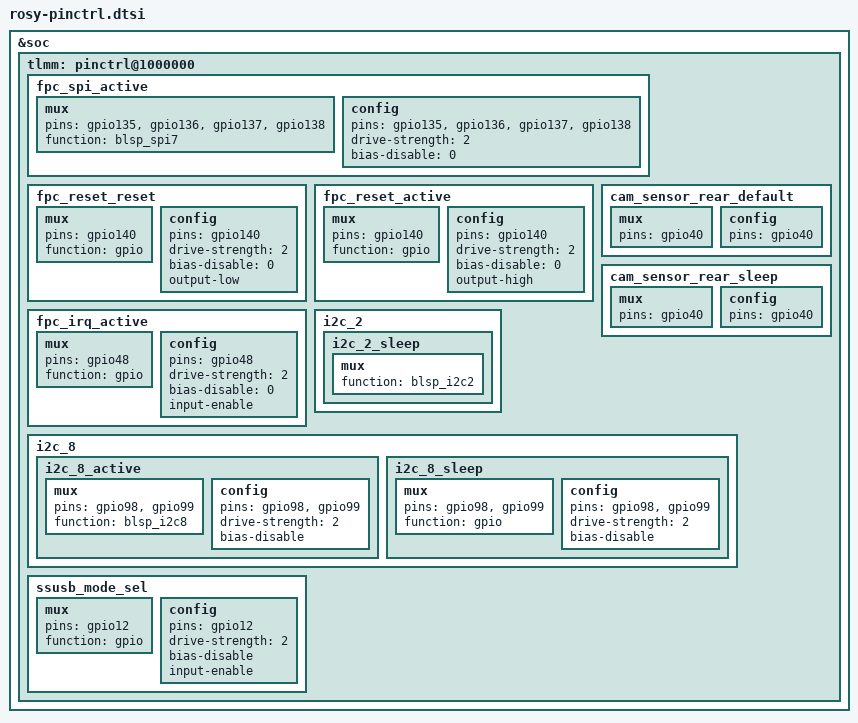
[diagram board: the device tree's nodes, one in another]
/*
 * Copyright (c) 2015-2018, The Linux Foundation. All rights reserved.
 * Copyright (C) 2019 XiaoMi, Inc.
 *
 * This program is free software; you can redistribute it and/or modify
 * it under the terms of the GNU General Public License version 2 and
 * only version 2 as published by the Free Software Foundation.
 *
 * This program is distributed in the hope that it will be useful,
 * but WITHOUT ANY WARRANTY; without even the implied warranty of
 * MERCHANTABILITY or FITNESS FOR A PARTICULAR PURPOSE.  See the
 * GNU General Public License for more details.
 */

&soc {
	tlmm: pinctrl@1000000 {
		fpc_spi_active: fpc_spi_active {
			mux {
				pins = "gpio135", "gpio136", "gpio137", "gpio138";
				function = "blsp_spi7";
			};

			config {
				pins = "gpio135", "gpio136", "gpio137", "gpio138";
				drive-strength = <2>;
				bias-disable = <0>;
			};
		};

		fpc_reset_reset: fpc_reset_reset{
			mux {
				pins = "gpio140";
				function = "gpio";
			};

			config {
				pins = "gpio140";
				drive-strength = <2>;
				bias-disable = <0>;
				output-low;
			};
		};

		fpc_reset_active: fpc_reset_active{
			mux {
				pins = "gpio140";
				function = "gpio";
			};

			config {
				pins = "gpio140";
				drive-strength = <2>;
				bias-disable = <0>;
				output-high;
			};
		};

		fpc_irq_active: fpc_irq_active {
			mux {
				pins = "gpio48";
				function = "gpio";
			};

			config {
				pins = "gpio48";
				drive-strength = <2>;
				bias-disable = <0>;
				input-enable;
			};
		};

		cam_sensor_rear_default: cam_sensor_rear_default {
			mux {
				pins = "gpio40";
			};

			config {
				pins = "gpio40";
			};
		};

		cam_sensor_rear_sleep: cam_sensor_rear_sleep {
			mux {
				pins = "gpio40";
			};

			config {
				pins = "gpio40";
			};
		};

		i2c_2 {
			i2c_2_sleep: i2c_2_sleep {
				mux {
					function = "blsp_i2c2";
				};
			};
		};

		i2c_8 {
			i2c_8_active: i2c_8_active{
				/* active state */
				mux{
					pins = "gpio98","gpio99";
					function = "blsp_i2c8";
				};

				config{
					pins = "gpio98","gpio99";
					drive-strength = <2>;
					bias-disable;
				};
			};

			i2c_8_sleep: i2c_8_sleep{
				/* suspended state */
				mux{
					pins = "gpio98","gpio99";
					function = "gpio";
				};

				config{
					pins = "gpio98","gpio99";
					drive-strength = <2>;
					bias-disable;
				};
			};
		};

		/delete-node/ typec_ssmux_config;

		ssusb_mode_sel: ssusb_mode_sel {
			mux {
				pins = "gpio12";
				function = "gpio";
			};

			config {
				pins = "gpio12";
				drive-strength = <2>;
				bias-disable;
				input-enable;
			};
		};
	};
};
